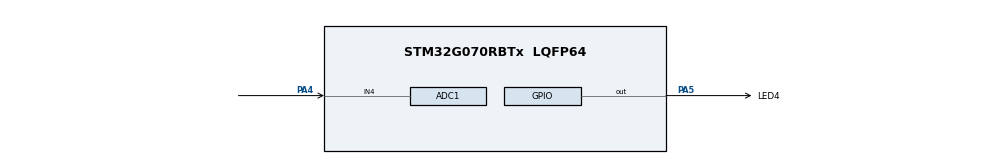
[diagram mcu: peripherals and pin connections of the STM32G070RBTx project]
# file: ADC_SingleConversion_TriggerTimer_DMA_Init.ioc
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ADC1.Channel-10\#ChannelRegularConversion=ADC_CHANNEL_4
ADC1.Channel-4\#ChannelRegularConversion=ADC_CHANNEL_4
ADC1.Channel-IN4=ADC_CHANNEL_4
ADC1.ClockPrescaler=ADC_CLOCK_SYNC_PCLK_DIV4
ADC1.DMAContinuousRequests=ENABLE
ADC1.EOCSelection=ADC_EOC_SEQ_CONV
ADC1.ExternalTrigConv=ADC_EXTERNALTRIG_T3_TRGO
ADC1.ExternalTrigConvEdge=ADC_EXTERNALTRIGCONVEDGE_FALLING
ADC1.Overrun=ADC_OVR_DATA_OVERWRITTEN
ADC1.SamplingTime-4\#ChannelRegularConversion=ADC_SAMPLINGTIME_COMMON_1
ADC1.SamplingTimeCommon1=ADC_SAMPLETIME_39CYCLES_5
ADC1.SamplingTimeCommon2=ADC_SAMPLETIME_39CYCLES_5
ADC1.SelectedChannel=ADC_CHANNEL_4
ADC1.master=1
Dma.ADC1.0.Direction=DMA_PERIPH_TO_MEMORY
Dma.ADC1.0.EventEnable=DISABLE
Dma.ADC1.0.Instance=DMA1_Channel1
Dma.ADC1.0.MemDataAlignment=DMA_MDATAALIGN_HALFWORD
Dma.ADC1.0.MemInc=DMA_MINC_ENABLE
Dma.ADC1.0.Mode=DMA_CIRCULAR
Dma.ADC1.0.PeriphDataAlignment=DMA_PDATAALIGN_HALFWORD
Dma.ADC1.0.PeriphInc=DMA_PINC_DISABLE
Dma.ADC1.0.Polarity=HAL_DMAMUX_REQUEST_GEN_RISING
Dma.ADC1.0.Priority=DMA_PRIORITY_HIGH
Dma.ADC1.0.RequestNumber=1
Dma.ADC1.0.SignalID=HAL_DMAMUX1_REQUEST_GEN_EXTI13
Dma.ADC1.0.SyncEnable=DISABLE
Dma.ADC1.0.SyncPolarity=HAL_DMAMUX_SYNC_NO_EVENT
Dma.ADC1.0.SyncRequestNumber=1
Dma.ADC1.0.SyncSignalID=HAL_DMAMUX1_SYNC_EXTI13
Dma.Request0=ADC1
Mcu.Family=STM32G0
Mcu.Name=STM32G070RBTx
Mcu.Package=LQFP64
NVIC.DMA1_Channel1_IRQn=true\:1\:0\:true\:false\:true\:false\:true\:true
PA4.GPIO_Mode=GPIO_MODE_ANALOG
PA4.Mode=IN4
PA4.Signal=ADC1_IN4
PA5.GPIO_Label=LED4
PA5.Signal=GPIO_Output
ProjectManager.HeapSize=0x200
ProjectManager.StackSize=0x400
ProjectManager.TargetToolchain=EWARM V8.50
RCC.ADCFreq_Value=16000000
RCC.AHBFreq_Value=16000000
RCC.CodegenConfigPeriph=false
RCC.CortexFreq_Value=16000000
RCC.EXTERNAL_CLOCK_VALUE=48000
RCC.HCLKFreq_Value=16000000
RCC.HSE_VALUE=8000000
RCC.HSI_VALUE=16000000
RCC.LSE_VALUE=32768
RCC.PLLM=RCC_PLLM_DIV4
RCC.PLLN=70
RCC.PLLP=RCC_PLLP_DIV10
RCC.PLLQ=RCC_PLLQ_DIV5
RCC.PLLR=RCC_PLLR_DIV5
RCC.SYSCLKFreq_VALUE=16000000
RCC.VCOOutputFreq_Value=280000000
TIM3.ClockPrescaler=ADC_CLOCK_SYNC_PCLK_DIV4
TIM3.ExternalTrigConv=ADC_EXTERNALTRIG_T3_TRGO
TIM3.Period=(timer_reload - 1)
TIM3.Prescaler=(timer_prescaler - 1)
TIM3.SamplingTime-4\#ChannelRegularConversion=ADC_SAMPLINGTIME_COMMON_1
TIM3.TIM_MasterOutputTrigger=TIM_TRGO_UPDATE
VP_SYS_VS_DBSignals.Mode=DisableDeadBatterySignals
VP_TIM3_VS_ClockSourceITR.Mode=TriggerSource_ITR0
board=custom

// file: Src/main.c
/* USER CODE BEGIN Header */
/**
  ******************************************************************************
  * @file    Examples_LL/ADC/ADC_SingleConversion_TriggerTimer_DMA_Init/Src/main.c
  * @author  MCD Application Team
  * @brief   This example describes how to use a ADC peripheral to perform
  *          a single ADC conversion of a channel, at each trigger event
  *          from timer.
  *          Conversion data are transferred by DMA into a table,
  *          indefinitely (circular mode).
  *          This example is based on the STM32G0xx ADC LL API;
  *          Peripheral initialization done using LL unitary services functions.
  ******************************************************************************
  * @attention
  *
  * Copyright (c) 2018-2021 STMicroelectronics.
  * All rights reserved.
  *
  * This software is licensed under terms that can be found in the LICENSE file
  * in the root directory of this software component.
  * If no LICENSE file comes with this software, it is provided AS-IS.
  *
  ******************************************************************************
  */
/* USER CODE END Header */
#include "main.h"

/* USER CODE BEGIN PD */

/* Definitions of ADC hardware constraints delays */
/* Note: Only ADC IP HW delays are defined in ADC LL driver driver,           */
/*       not timeout values:                                                  */
/*       Timeout values for ADC operations are dependent to device clock      */
/*       configuration (system clock versus ADC clock),                       */
/*       and therefore must be defined in user application.                   */
/*       Refer to @ref ADC_LL_EC_HW_DELAYS for description of ADC timeout     */
/*       values definition.                                                   */

  /* Timeout values for ADC operations. */
  /* (calibration, enable settling time, disable settling time, ...)          */
  /* Values defined to be higher than worst cases: low clock frequency,       */
  /* maximum prescalers.                                                      */
  /* Unit: ms                                                                 */
  #define ADC_CALIBRATION_TIMEOUT_MS       (   1U)
  #define ADC_ENABLE_TIMEOUT_MS            (   1U)
  #define ADC_DISABLE_TIMEOUT_MS           (   1U)
  #define ADC_STOP_CONVERSION_TIMEOUT_MS   (   1U)
  #define ADC_CONVERSION_TIMEOUT_MS        (4000U)

  /* Delay between ADC end of calibration and ADC enable.                     */
  /* Delay estimation in CPU cycles: Case of ADC enable done                  */
  /* immediately after ADC calibration, ADC clock setting slow                */
  /* (LL_ADC_CLOCK_ASYNC_DIV32). Use a higher delay if ratio                  */
  /* (CPU clock / ADC clock) is above 32.                                     */
  #define ADC_DELAY_CALIB_ENABLE_CPU_CYCLES  (LL_ADC_DELAY_CALIB_ENABLE_ADC_CYCLES * 32)

/* Definitions of environment analog values */
  /* Value of analog reference voltage (Vref+), connected to analog voltage   */
  /* supply Vdda (unit: mV).                                                  */
  #define VDDA_APPLI                       (3300U)

/* Definitions of data related to this example */
  /* Definition of ADCx conversions data table size */
  #define ADC_CONVERTED_DATA_BUFFER_SIZE   (  64U)

  /* Init variable out of expected ADC conversion data range */
  #define VAR_CONVERTED_DATA_INIT_VALUE    (__LL_ADC_DIGITAL_SCALE(LL_ADC_RESOLUTION_12B) + 1)

  /* Parameters of timer (used as ADC conversion trigger) */
  /* Timer frequency (unit: Hz). With a timer 16 bits and time base           */
  /* freq min 1Hz, range is min=1Hz, max=32kHz.                               */
  #define TIMER_FREQUENCY                (1000U)
  /* Timer minimum frequency (unit: Hz), used to calculate frequency range.   */
  /* With a timer 16 bits, maximum frequency will be 32000 times this value.  */
  #define TIMER_FREQUENCY_RANGE_MIN      (   1U)
  /* Timer prescaler maximum value (0xFFFF for a timer 16 bits)               */
  #define TIMER_PRESCALER_MAX_VALUE      (0xFFFF - 1U)

/* USER CODE END PD */

/* USER CODE BEGIN PV */

/* Variables for ADC conversion data */
__IO uint16_t aADCxConvertedData[ADC_CONVERTED_DATA_BUFFER_SIZE]; /* ADC group regular conversion data */

/* Variables for ADC conversion data computation to physical values */
__IO uint16_t aADCxConvertedData_Voltage_mVolt[ADC_CONVERTED_DATA_BUFFER_SIZE];  /* Value of voltage calculated from ADC conversion data (unit: mV) (array of data) */

/* Variable to report status of DMA transfer of ADC group regular conversions */
/*  0: DMA transfer is not completed                                          */
/*  1: DMA transfer is completed                                              */
/*  2: DMA transfer has not yet been started yet (initial state)              */
__IO uint8_t ubDmaTransferStatus = 2U; /* Variable set into DMA interruption callback */

/* USER CODE END PV */

void SystemClock_Config(void);
static void MX_GPIO_Init(void);
static void MX_DMA_Init(void);
static void MX_ADC1_Init(void);
static void MX_TIM3_Init(void);
/* USER CODE BEGIN PFP */
void     Activate_ADC(void);
void     LED_On(void);
void     LED_Off(void);
void     LED_Blinking(uint32_t Period);
void     UserButton_Init(void);
/* USER CODE END PFP */

int main(void)
{
  /* USER CODE BEGIN 1 */

  uint32_t tmp_index_adc_converted_data = 0U;

  /* USER CODE END 1 */

  /* MCU Configuration--------------------------------------------------------*/

  /* Reset of all peripherals, Initializes the Flash interface and the Systick. */
  LL_APB2_GRP1_EnableClock(LL_APB2_GRP1_PERIPH_SYSCFG);
  LL_APB1_GRP1_EnableClock(LL_APB1_GRP1_PERIPH_PWR);

  /** Disable the internal Pull-Up in Dead Battery pins of UCPD peripheral
  */
  LL_SYSCFG_DisableDBATT(LL_SYSCFG_UCPD1_STROBE | LL_SYSCFG_UCPD2_STROBE);

  /* Configure the system clock */
  SystemClock_Config();

  /* USER CODE BEGIN SysInit */

  /* Init variable containing ADC conversion data */
  for (tmp_index_adc_converted_data = 0; tmp_index_adc_converted_data < ADC_CONVERTED_DATA_BUFFER_SIZE; tmp_index_adc_converted_data++)
  {
    aADCxConvertedData[tmp_index_adc_converted_data] = VAR_CONVERTED_DATA_INIT_VALUE;
  }
  /* USER CODE END SysInit */

  /* Initialize all configured peripherals */
  MX_GPIO_Init();
  MX_DMA_Init();
  MX_ADC1_Init();
  MX_TIM3_Init();
  /* USER CODE BEGIN 2 */

  /* Initialize button in EXTI mode */
  UserButton_Init();

  /* Activate ADC */
  /* Perform ADC activation procedure to make it ready to convert. */
  Activate_ADC();

  /* USER CODE END 2 */

  /* Infinite loop */
  /* USER CODE BEGIN WHILE */
  while (1)
  {
    /* Note: ADC group regular conversion start is done into push button      */
    /*       IRQ handler, refer to function "UserButton_Callback()".          */
    /*       Then, ADC conversions are performed indefinitely (trigger from   */
    /*       timer: ADC conversions as long as timer is running).             */

    /* Note: LED state depending on DMA transfer status is set into DMA       */
    /*       IRQ handler,                                                     */
    /*       refer to functions "AdcDmaTransferComplete_Callback()"           */
    /*       and "AdcDmaTransferHalf_Callback()".                             */

    /* Note: ADC conversions data are stored into array                       */
    /*       "aADCxConvertedData"                                             */
    /*       (for debug: see variable content into watch window).             */

    /* Note: ADC conversion data are computed to physical values              */
    /*       into array "aADCxConvertedData_Voltage_mVolt"                    */
    /*       using ADC LL driver helper macro "__LL_ADC_CALC_DATA_TO_VOLTAGE()". */
    /*       (for debug: see variable content into watch window).             */

    /* USER CODE END WHILE */

  }
}

void SystemClock_Config(void)
{
  /* HSI configuration and activation */
  LL_RCC_HSI_Enable();
  while(LL_RCC_HSI_IsReady() != 1)
  {
  }

  /* Set AHB prescaler*/
  LL_RCC_SetAHBPrescaler(LL_RCC_SYSCLK_DIV_1);

  /* Sysclk activation on the HSI */
  LL_RCC_SetSysClkSource(LL_RCC_SYS_CLKSOURCE_HSI);
  while(LL_RCC_GetSysClkSource() != LL_RCC_SYS_CLKSOURCE_STATUS_HSI)
  {
  }

  /* Set APB1 prescaler*/
  LL_RCC_SetAPB1Prescaler(LL_RCC_APB1_DIV_1);
  LL_Init1msTick(16000000);
  /* Update CMSIS variable (which can be updated also through SystemCoreClockUpdate function) */
  LL_SetSystemCoreClock(16000000);
}

static void MX_ADC1_Init(void)
{

  LL_ADC_InitTypeDef ADC_InitStruct = {0};
  LL_ADC_REG_InitTypeDef ADC_REG_InitStruct = {0};

  LL_GPIO_InitTypeDef GPIO_InitStruct = {0};

  /* Peripheral clock enable */
  LL_APB2_GRP1_EnableClock(LL_APB2_GRP1_PERIPH_ADC);

  LL_IOP_GRP1_EnableClock(LL_IOP_GRP1_PERIPH_GPIOA);
  /**ADC1 GPIO Configuration
  PA4   ------> ADC1_IN4
  */
  GPIO_InitStruct.Pin = LL_GPIO_PIN_4;
  GPIO_InitStruct.Mode = LL_GPIO_MODE_ANALOG;
  GPIO_InitStruct.Pull = LL_GPIO_PULL_NO;
  LL_GPIO_Init(GPIOA, &GPIO_InitStruct);

  /* ADC1 DMA Init */

  /* ADC1 Init */
  LL_DMA_SetPeriphRequest(DMA1, LL_DMA_CHANNEL_1, LL_DMAMUX_REQ_ADC1);

  LL_DMA_SetDataTransferDirection(DMA1, LL_DMA_CHANNEL_1, LL_DMA_DIRECTION_PERIPH_TO_MEMORY);

  LL_DMA_SetChannelPriorityLevel(DMA1, LL_DMA_CHANNEL_1, LL_DMA_PRIORITY_HIGH);

  LL_DMA_SetMode(DMA1, LL_DMA_CHANNEL_1, LL_DMA_MODE_CIRCULAR);

  LL_DMA_SetPeriphIncMode(DMA1, LL_DMA_CHANNEL_1, LL_DMA_PERIPH_NOINCREMENT);

  LL_DMA_SetMemoryIncMode(DMA1, LL_DMA_CHANNEL_1, LL_DMA_MEMORY_INCREMENT);

  LL_DMA_SetPeriphSize(DMA1, LL_DMA_CHANNEL_1, LL_DMA_PDATAALIGN_HALFWORD);

  LL_DMA_SetMemorySize(DMA1, LL_DMA_CHANNEL_1, LL_DMA_MDATAALIGN_HALFWORD);

  /* USER CODE BEGIN ADC1_Init 1 */

  /* Select ADC as DMA transfer request */
  LL_DMAMUX_SetRequestID(DMAMUX1,
                         LL_DMAMUX_CHANNEL_0,
                         LL_DMAMUX_REQ_ADC1);

  /* Set DMA transfer addresses of source and destination */
  LL_DMA_ConfigAddresses(DMA1,
                         LL_DMA_CHANNEL_1,
                         LL_ADC_DMA_GetRegAddr(ADC1, LL_ADC_DMA_REG_REGULAR_DATA),
                         (uint32_t)&aADCxConvertedData,
                         LL_DMA_DIRECTION_PERIPH_TO_MEMORY);

  /* Set DMA transfer size */
  LL_DMA_SetDataLength(DMA1,
                       LL_DMA_CHANNEL_1,
                       ADC_CONVERTED_DATA_BUFFER_SIZE);

  /* Enable DMA transfer interruption: transfer complete */
  LL_DMA_EnableIT_TC(DMA1,
                     LL_DMA_CHANNEL_1);

  /* Enable DMA transfer interruption: half transfer */
  LL_DMA_EnableIT_HT(DMA1,
                     LL_DMA_CHANNEL_1);

  /* Enable DMA transfer interruption: transfer error */
  LL_DMA_EnableIT_TE(DMA1,
                     LL_DMA_CHANNEL_1);

  /*## Activation of DMA #####################################################*/
  /* Enable the DMA transfer */
  LL_DMA_EnableChannel(DMA1,
                       LL_DMA_CHANNEL_1);
  /* Configure NVIC to enable ADC1 interruptions */
  NVIC_SetPriority(ADC1_IRQn, 0);
  NVIC_EnableIRQ(ADC1_IRQn);
  /* USER CODE END ADC1_Init 1 */

  /** Configure the global features of the ADC (Clock, Resolution, Data Alignment and number of conversion)
  */

   #define ADC_CHANNEL_CONF_RDY_TIMEOUT_MS ( 1U)
   #if (USE_TIMEOUT == 1)
   uint32_t Timeout ; /* Variable used for Timeout management */
   #endif /* USE_TIMEOUT */

  ADC_InitStruct.Clock = LL_ADC_CLOCK_SYNC_PCLK_DIV4;
  ADC_InitStruct.Resolution = LL_ADC_RESOLUTION_12B;
  ADC_InitStruct.DataAlignment = LL_ADC_DATA_ALIGN_RIGHT;
  ADC_InitStruct.LowPowerMode = LL_ADC_LP_MODE_NONE;
  LL_ADC_Init(ADC1, &ADC_InitStruct);
  LL_ADC_REG_SetSequencerConfigurable(ADC1, LL_ADC_REG_SEQ_CONFIGURABLE);

   /* Poll for ADC channel configuration ready */
   #if (USE_TIMEOUT == 1)
   Timeout = ADC_CHANNEL_CONF_RDY_TIMEOUT_MS;
   #endif /* USE_TIMEOUT */
   while (LL_ADC_IsActiveFlag_CCRDY(ADC1) == 0)
     {
   #if (USE_TIMEOUT == 1)
   /* Check Systick counter flag to decrement the time-out value */
   if (LL_SYSTICK_IsActiveCounterFlag())
     {
   if(Timeout-- == 0)
         {
   Error_Handler();
         }
     }
   #endif /* USE_TIMEOUT */
     }
   /* Clear flag ADC channel configuration ready */
   LL_ADC_ClearFlag_CCRDY(ADC1);
  ADC_REG_InitStruct.TriggerSource = LL_ADC_REG_TRIG_EXT_TIM3_TRGO;
  ADC_REG_InitStruct.SequencerLength = LL_ADC_REG_SEQ_SCAN_DISABLE;
  ADC_REG_InitStruct.SequencerDiscont = LL_ADC_REG_SEQ_DISCONT_DISABLE;
  ADC_REG_InitStruct.ContinuousMode = LL_ADC_REG_CONV_SINGLE;
  ADC_REG_InitStruct.DMATransfer = LL_ADC_REG_DMA_TRANSFER_UNLIMITED;
  ADC_REG_InitStruct.Overrun = LL_ADC_REG_OVR_DATA_OVERWRITTEN;
  LL_ADC_REG_Init(ADC1, &ADC_REG_InitStruct);
  LL_ADC_SetOverSamplingScope(ADC1, LL_ADC_OVS_DISABLE);
  LL_ADC_SetTriggerFrequencyMode(ADC1, LL_ADC_CLOCK_FREQ_MODE_HIGH);
  LL_ADC_REG_SetTriggerEdge(ADC1, LL_ADC_REG_TRIG_EXT_FALLING);
  LL_ADC_SetSamplingTimeCommonChannels(ADC1, LL_ADC_SAMPLINGTIME_COMMON_1, LL_ADC_SAMPLINGTIME_39CYCLES_5);
  LL_ADC_SetSamplingTimeCommonChannels(ADC1, LL_ADC_SAMPLINGTIME_COMMON_2, LL_ADC_SAMPLINGTIME_39CYCLES_5);
  LL_ADC_DisableIT_EOC(ADC1);
  LL_ADC_DisableIT_EOS(ADC1);

   /* Enable ADC internal voltage regulator */
   LL_ADC_EnableInternalRegulator(ADC1);
   /* Delay for ADC internal voltage regulator stabilization. */
   /* Compute number of CPU cycles to wait for, from delay in us. */
   /* Note: Variable divided by 2 to compensate partially */
   /* CPU processing cycles (depends on compilation optimization). */
   /* Note: If system core clock frequency is below 200kHz, wait time */
   /* is only a few CPU processing cycles. */
   uint32_t wait_loop_index;
   wait_loop_index = ((LL_ADC_DELAY_INTERNAL_REGUL_STAB_US * (SystemCoreClock / (100000 * 2))) / 10);
   while(wait_loop_index != 0)
     {
   wait_loop_index--;
     }

  /** Configure Regular Channel
  */
  LL_ADC_REG_SetSequencerRanks(ADC1, LL_ADC_REG_RANK_1, LL_ADC_CHANNEL_4);

   /* Poll for ADC channel configuration ready */
   #if (USE_TIMEOUT == 1)
   Timeout = ADC_CHANNEL_CONF_RDY_TIMEOUT_MS;
   #endif /* USE_TIMEOUT */
   while (LL_ADC_IsActiveFlag_CCRDY(ADC1) == 0)
     {
   #if (USE_TIMEOUT == 1)
   /* Check Systick counter flag to decrement the time-out value */
   if (LL_SYSTICK_IsActiveCounterFlag())
     {
   if(Timeout-- == 0)
         {
   Error_Handler();
         }
     }
   #endif /* USE_TIMEOUT */
     }
   /* Clear flag ADC channel configuration ready */
   LL_ADC_ClearFlag_CCRDY(ADC1);
  LL_ADC_SetChannelSamplingTime(ADC1, LL_ADC_CHANNEL_4, LL_ADC_SAMPLINGTIME_COMMON_1);

  /** Configure Regular Channel
  */
  LL_ADC_REG_SetSequencerRanks(ADC1, LL_ADC_REG_RANK_1, LL_ADC_CHANNEL_4);

   /* Poll for ADC channel configuration ready */
   #if (USE_TIMEOUT == 1)
   Timeout = ADC_CHANNEL_CONF_RDY_TIMEOUT_MS;
   #endif /* USE_TIMEOUT */
   while (LL_ADC_IsActiveFlag_CCRDY(ADC1) == 0)
     {
   #if (USE_TIMEOUT == 1)
   /* Check Systick counter flag to decrement the time-out value */
   if (LL_SYSTICK_IsActiveCounterFlag())
     {
   if(Timeout-- == 0)
         {
   Error_Handler();
         }
     }
   #endif /* USE_TIMEOUT */
     }
   /* Clear flag ADC channel configuration ready */
   LL_ADC_ClearFlag_CCRDY(ADC1);
  LL_ADC_SetChannelSamplingTime(ADC1, LL_ADC_CHANNEL_4, LL_ADC_SAMPLINGTIME_COMMON_1);
  /* USER CODE BEGIN ADC1_Init 2 */

  /* Enable interruption ADC group regular overrun */
  LL_ADC_EnableIT_OVR(ADC1);
  /* USER CODE END ADC1_Init 2 */

}

static void MX_TIM3_Init(void)
{

  /* USER CODE BEGIN TIM3_Init 0 */
  uint32_t timer_clock_frequency = 0;             /* Timer clock frequency */
  uint32_t timer_prescaler = 0;                   /* Time base prescaler to have timebase aligned on minimum frequency possible */
  uint32_t timer_reload = 0;                      /* Timer reload value in function of timer prescaler to achieve time base period */
  /* USER CODE END TIM3_Init 0 */

  LL_TIM_InitTypeDef TIM_InitStruct = {0};

  /* Peripheral clock enable */
  LL_APB1_GRP1_EnableClock(LL_APB1_GRP1_PERIPH_TIM3);

  /* USER CODE BEGIN TIM3_Init 1 */
  /*## Configuration of NVIC #################################################*/
  /* Note: In this example, timer interrupts are not activated.               */
  /*       If needed, timer interruption at each time base period is          */
  /*       possible.                                                          */
  /*       Refer to timer examples.                                           */
  /* Configuration of timer as time base:                                     */
  /* Caution: Computation of frequency is done for a timer instance on APB1   */
  /*          (clocked by PCLK1)                                              */
  /* Timer frequency is configured from the following constants:              */
  /* - TIMER_FREQUENCY: timer frequency (unit: Hz).                           */
  /* - TIMER_FREQUENCY_RANGE_MIN: timer minimum frequency possible            */
  /*   (unit: Hz).                                                            */
  /* Note: Refer to comments at these literals definition for more details.   */

  /* Retrieve timer clock source frequency */
  /* If APB1 prescaler is different of 1, timers have a factor x2 on their    */
  /* clock source.                                                            */
  if (LL_RCC_GetAPB1Prescaler() == LL_RCC_APB1_DIV_1)
  {
    timer_clock_frequency = __LL_RCC_CALC_PCLK1_FREQ(SystemCoreClock, LL_RCC_GetAPB1Prescaler());
  }
  else
  {
    timer_clock_frequency = (__LL_RCC_CALC_PCLK1_FREQ(SystemCoreClock, LL_RCC_GetAPB1Prescaler()) * 2);
  }

  /* Timer prescaler calculation */
  /* (computation for timer 16 bits, additional + 1 to round the prescaler up) */
  timer_prescaler = ((timer_clock_frequency / (TIMER_PRESCALER_MAX_VALUE * TIMER_FREQUENCY_RANGE_MIN)) +1);
  /* Timer reload calculation */
  timer_reload = (timer_clock_frequency / (timer_prescaler * TIMER_FREQUENCY));

  /* USER CODE END TIM3_Init 1 */
  TIM_InitStruct.Prescaler = (timer_prescaler - 1);
  TIM_InitStruct.CounterMode = LL_TIM_COUNTERMODE_UP;
  TIM_InitStruct.Autoreload = (timer_reload - 1);
  TIM_InitStruct.ClockDivision = LL_TIM_CLOCKDIVISION_DIV1;
  LL_TIM_Init(TIM3, &TIM_InitStruct);
  LL_TIM_DisableARRPreload(TIM3);
  LL_TIM_SetTriggerInput(TIM3, LL_TIM_TS_ITR0);
  LL_TIM_SetSlaveMode(TIM3, LL_TIM_SLAVEMODE_DISABLED);
  LL_TIM_DisableIT_TRIG(TIM3);
  LL_TIM_DisableDMAReq_TRIG(TIM3);
  LL_TIM_SetTriggerOutput(TIM3, LL_TIM_TRGO_UPDATE);
  LL_TIM_DisableMasterSlaveMode(TIM3);
  /* USER CODE BEGIN TIM3_Init 2 */
  /* Set timer the trigger output (TRGO) */
  LL_TIM_SetTriggerOutput(TIM3, LL_TIM_TRGO_UPDATE);
  /* Enable counter */
  LL_TIM_EnableCounter(TIM3);
  /* USER CODE END TIM3_Init 2 */

}

static void MX_DMA_Init(void)
{

  /* Init with LL driver */
  /* DMA controller clock enable */
  LL_AHB1_GRP1_EnableClock(LL_AHB1_GRP1_PERIPH_DMA1);

  /* DMA interrupt init */
  /* DMA1_Channel1_IRQn interrupt configuration */
  NVIC_SetPriority(DMA1_Channel1_IRQn, 1);
  NVIC_EnableIRQ(DMA1_Channel1_IRQn);

}

static void MX_GPIO_Init(void)
{
  LL_GPIO_InitTypeDef GPIO_InitStruct = {0};

  /* GPIO Ports Clock Enable */
  LL_IOP_GRP1_EnableClock(LL_IOP_GRP1_PERIPH_GPIOA);

  /**/
  LL_GPIO_ResetOutputPin(LED4_GPIO_Port, LED4_Pin);

  /**/
  GPIO_InitStruct.Pin = LED4_Pin;
  GPIO_InitStruct.Mode = LL_GPIO_MODE_OUTPUT;
  GPIO_InitStruct.Speed = LL_GPIO_SPEED_FREQ_LOW;
  GPIO_InitStruct.OutputType = LL_GPIO_OUTPUT_PUSHPULL;
  GPIO_InitStruct.Pull = LL_GPIO_PULL_NO;
  LL_GPIO_Init(LED4_GPIO_Port, &GPIO_InitStruct);

}

/* USER CODE BEGIN 4 */

/**
  * @brief  Perform ADC activation procedure to make it ready to convert
  *         (ADC instance: ADC1).
  * @note   Operations:
  *         - ADC instance
  *           - Run ADC self calibration
  *           - Enable ADC
  *         - ADC group regular
  *           none: ADC conversion start-stop to be performed
  *                 after this function
  *         - ADC group injected
  *           Feature not available                                  (feature not available on this STM32 series)
  * @param  None
  * @retval None
  */
void Activate_ADC(void)
{
  __IO uint32_t wait_loop_index = 0U;
  __IO uint32_t backup_setting_adc_dma_transfer = 0U;
  #if (USE_TIMEOUT == 1)
  uint32_t Timeout = 0U; /* Variable used for timeout management */
  #endif /* USE_TIMEOUT */

  /*## Operation on ADC hierarchical scope: ADC instance #####################*/

  /* Note: Hardware constraint (refer to description of the functions         */
  /*       below):                                                            */
  /*       On this STM32 series, setting of these features is conditioned to  */
  /*       ADC state:                                                         */
  /*       ADC must be disabled.                                              */
  /* Note: In this example, all these checks are not necessary but are        */
  /*       implemented anyway to show the best practice usages                */
  /*       corresponding to reference manual procedure.                       */
  /*       Software can be optimized by removing some of these checks, if     */
  /*       they are not relevant considering previous settings and actions    */
  /*       in user application.                                               */
  if (LL_ADC_IsEnabled(ADC1) == 0)
  {
    /* Enable ADC internal voltage regulator */
    LL_ADC_EnableInternalRegulator(ADC1);

    /* Delay for ADC internal voltage regulator stabilization.                */
    /* Compute number of CPU cycles to wait for, from delay in us.            */
    /* Note: Variable divided by 2 to compensate partially                    */
    /*       CPU processing cycles (depends on compilation optimization).     */
    /* Note: If system core clock frequency is below 200kHz, wait time        */
    /*       is only a few CPU processing cycles.                             */
    wait_loop_index = ((LL_ADC_DELAY_INTERNAL_REGUL_STAB_US * (SystemCoreClock / (100000 * 2))) / 10);
    while(wait_loop_index != 0)
    {
      wait_loop_index--;
    }

    /* Disable ADC DMA transfer request during calibration */
    /* Note: Specificity of this STM32 series: Calibration factor is          */
    /*       available in data register and also transferred by DMA.          */
    /*       To not insert ADC calibration factor among ADC conversion data   */
    /*       in DMA destination address, DMA transfer must be disabled during */
    /*       calibration.                                                     */
    backup_setting_adc_dma_transfer = LL_ADC_REG_GetDMATransfer(ADC1);
    LL_ADC_REG_SetDMATransfer(ADC1, LL_ADC_REG_DMA_TRANSFER_NONE);

    /* Run ADC self calibration */
    LL_ADC_StartCalibration(ADC1);

    /* Poll for ADC effectively calibrated */
    #if (USE_TIMEOUT == 1)
    Timeout = ADC_CALIBRATION_TIMEOUT_MS;
    #endif /* USE_TIMEOUT */

    while (LL_ADC_IsCalibrationOnGoing(ADC1) != 0)
    {
    #if (USE_TIMEOUT == 1)
      /* Check Systick counter flag to decrement the time-out value */
      if (LL_SYSTICK_IsActiveCounterFlag())
      {
        if(Timeout-- == 0)
        {
        /* Time-out occurred. Set LED to blinking mode */
        LED_Blinking(LED_BLINK_ERROR);
        }
      }
    #endif /* USE_TIMEOUT */
    }

    /* Restore ADC DMA transfer request after calibration */
    LL_ADC_REG_SetDMATransfer(ADC1, backup_setting_adc_dma_transfer);

    /* Delay between ADC end of calibration and ADC enable.                   */
    /* Note: Variable divided by 2 to compensate partially                    */
    /*       CPU processing cycles (depends on compilation optimization).     */
    wait_loop_index = (ADC_DELAY_CALIB_ENABLE_CPU_CYCLES >> 1);
    while(wait_loop_index != 0)
    {
      wait_loop_index--;
    }

    /* Enable ADC */
    LL_ADC_Enable(ADC1);

    /* Poll for ADC ready to convert */
    #if (USE_TIMEOUT == 1)
    Timeout = ADC_ENABLE_TIMEOUT_MS;
    #endif /* USE_TIMEOUT */

    while (LL_ADC_IsActiveFlag_ADRDY(ADC1) == 0)
    {
    #if (USE_TIMEOUT == 1)
      /* Check Systick counter flag to decrement the time-out value */
      if (LL_SYSTICK_IsActiveCounterFlag())
      {
        if(Timeout-- == 0)
        {
        /* Time-out occurred. Set LED to blinking mode */
        LED_Blinking(LED_BLINK_ERROR);
        }
      }
    #endif /* USE_TIMEOUT */
    }

    /* Note: ADC flag ADRDY is not cleared here to be able to check ADC       */
    /*       status afterwards.                                               */
    /*       This flag should be cleared at ADC Deactivation, before a new    */
    /*       ADC activation, using function "LL_ADC_ClearFlag_ADRDY()".       */
  }

  /*## Operation on ADC hierarchical scope: ADC group regular ################*/
  /* Note: No operation on ADC group regular performed here.                  */
  /*       ADC group regular conversions to be performed after this function  */
  /*       using function:                                                    */
  /*       "LL_ADC_REG_StartConversion();"                                    */

  /*## Operation on ADC hierarchical scope: ADC group injected ###############*/
  /* Note: Feature not available on this STM32 series */

}

/**
  * @brief  Turn-on LED4.
  * @param  None
  * @retval None
  */
void LED_On(void)
{
  /* Turn LED4 on */
  LL_GPIO_SetOutputPin(LED4_GPIO_Port, LED4_Pin);
}

/**
  * @brief  Turn-off LED4.
  * @param  None
  * @retval None
  */
void LED_Off(void)
{
  /* Turn LED4 off */
  LL_GPIO_ResetOutputPin(LED4_GPIO_Port, LED4_Pin);
}

/**
  * @brief  Set LED4 to Blinking mode for an infinite loop (toggle period based on value provided as input parameter).
  * @param  Period : Period of time (in ms) between each toggling of LED
  *   This parameter can be user defined values. Pre-defined values used in that example are :
  *     @arg LED_BLINK_FAST : Fast Blinking
  *     @arg LED_BLINK_SLOW : Slow Blinking
  *     @arg LED_BLINK_ERROR : Error specific Blinking
  * @retval None
  */
void LED_Blinking(uint32_t Period)
{
  /* Turn LED4 on */
  LL_GPIO_SetOutputPin(LED4_GPIO_Port, LED4_Pin);

  /* Toggle IO in an infinite loop */
  while (1)
  {
    LL_GPIO_TogglePin(LED4_GPIO_Port, LED4_Pin);
    LL_mDelay(Period);
  }
}

/**
  * @brief  Configures User push-button in EXTI Line Mode.
  * @param  None
  * @retval None
  */
void UserButton_Init(void)
{
  /* Enable the BUTTON Clock */
  USER_BUTTON_GPIO_CLK_ENABLE();

  /* Configure GPIO for BUTTON */
  LL_GPIO_SetPinMode(USER_BUTTON_GPIO_PORT, USER_BUTTON_PIN, LL_GPIO_MODE_INPUT);
  LL_GPIO_SetPinPull(USER_BUTTON_GPIO_PORT, USER_BUTTON_PIN, LL_GPIO_PULL_UP);

  /* if(Button_Mode == BUTTON_MODE_EXTI) */
  {
    /* Connect External Line to the GPIO */
    USER_BUTTON_SYSCFG_SET_EXTI();

    /* Enable a rising trigger EXTI line 13 Interrupt */
    USER_BUTTON_EXTI_LINE_ENABLE();
    USER_BUTTON_EXTI_FALLING_TRIG_ENABLE();

    /* Configure NVIC for USER_BUTTON_EXTI_IRQn */
    NVIC_EnableIRQ(USER_BUTTON_EXTI_IRQn);
    NVIC_SetPriority(USER_BUTTON_EXTI_IRQn,0x03);
  }
}

/******************************************************************************/
/*   USER IRQ HANDLER TREATMENT                                               */
/******************************************************************************/

/**
  * @brief  Function to manage IRQ Handler
  * @param  None
  * @retval None
  */
void UserButton_Callback(void)
{
  /* Start ADC conversion only on the first press on push button              */
  if (ubDmaTransferStatus == 2)
  {
    /* Update status variable of DMA transfer */
    ubDmaTransferStatus = 0;

  /* Start ADC group regular conversion */
  /* Note: Hardware constraint (refer to description of the function          */
  /*       below):                                                            */
  /*       On this STM32 series, setting of this feature is conditioned to    */
  /*       ADC state:                                                         */
  /*       ADC must be enabled without conversion on going on group regular,  */
  /*       without ADC disable command on going.                              */
  /* Note: In this example, all these checks are not necessary but are        */
  /*       implemented anyway to show the best practice usages                */
  /*       corresponding to reference manual procedure.                       */
  /*       Software can be optimized by removing some of these checks, if     */
  /*       they are not relevant considering previous settings and actions    */
  /*       in user application.                                               */
  if ((LL_ADC_IsEnabled(ADC1) == 1)               &&
      (LL_ADC_IsDisableOngoing(ADC1) == 0)        &&
      (LL_ADC_REG_IsConversionOngoing(ADC1) == 0)   )
  {
    LL_ADC_REG_StartConversion(ADC1);
  }
  else
  {
    /* Error: ADC conversion start could not be performed */
    LED_Blinking(LED_BLINK_ERROR);
  }
  }
}

/**
  * @brief  DMA transfer complete callback
  * @note   This function is executed when the transfer complete interrupt
  *         is generated
  * @retval None
  */
void AdcDmaTransferComplete_Callback()
{
  uint32_t tmp_index = 0;

  /* Computation of ADC conversions raw data to physical values               */
  /* using LL ADC driver helper macro.                                        */
  /* Management of the 2nd half of the buffer */
  for (tmp_index = (ADC_CONVERTED_DATA_BUFFER_SIZE/2); tmp_index < ADC_CONVERTED_DATA_BUFFER_SIZE; tmp_index++)
  {
    aADCxConvertedData_Voltage_mVolt[tmp_index] = __LL_ADC_CALC_DATA_TO_VOLTAGE(VDDA_APPLI, aADCxConvertedData[tmp_index], LL_ADC_RESOLUTION_12B);
  }

  /* Update status variable of DMA transfer */
  ubDmaTransferStatus = 1;

  /* Set LED depending on DMA transfer status */
  /* - Turn-on if DMA transfer is completed */
  /* - Turn-off if DMA transfer is not completed */
  LED_On();

}

/**
  * @brief  DMA half transfer callback
  * @note   This function is executed when the half transfer interrupt
  *         is generated
  * @retval None
  */
void AdcDmaTransferHalf_Callback()
{
  uint32_t tmp_index = 0;

  /* Computation of ADC conversions raw data to physical values               */
  /* using LL ADC driver helper macro.                                        */
  /* Management of the 1st half of the buffer */
  for (tmp_index = 0; tmp_index < (ADC_CONVERTED_DATA_BUFFER_SIZE/2); tmp_index++)
  {
    aADCxConvertedData_Voltage_mVolt[tmp_index] = __LL_ADC_CALC_DATA_TO_VOLTAGE(VDDA_APPLI, aADCxConvertedData[tmp_index], LL_ADC_RESOLUTION_12B);
  }

  /* Update status variable of DMA transfer */
  ubDmaTransferStatus = 0;

  /* Set LED depending on DMA transfer status */
  /* - Turn-on if DMA transfer is completed */
  /* - Turn-off if DMA transfer is not completed */
  LED_Off();

}

/**
  * @brief  DMA transfer error callback
  * @note   This function is executed when the transfer error interrupt
  *         is generated during DMA transfer
  * @retval None
  */
void AdcDmaTransferError_Callback()
{
  /* Error detected during DMA transfer */
  LED_Blinking(LED_BLINK_ERROR);
}

/**
  * @brief  ADC group regular overrun interruption callback
  * @note   This function is executed when ADC group regular
  *         overrun error occurs.
  * @retval None
  */
void AdcGrpRegularOverrunError_Callback(void)
{
  /* Note: Disable ADC interruption that caused this error before entering in */
  /*       infinite loop below.                                               */

  /* Disable ADC group regular overrun interruption */
  LL_ADC_DisableIT_OVR(ADC1);

  /* Error from ADC */
  LED_Blinking(LED_BLINK_ERROR);
}

/* USER CODE END 4 */

void Error_Handler(void)
{
}
